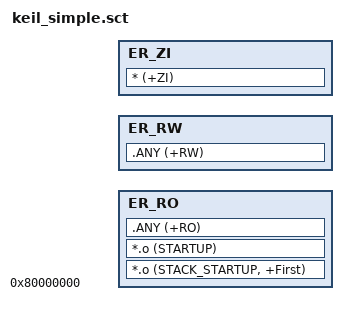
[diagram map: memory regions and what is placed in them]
; *************************************************************
; *** Scatter-Loading Description File generated by uVision ***
; *************************************************************
; Use SDRAM at EMC_DYCS0 (32MByte x 32-bits)

LR_SDRAM 0x80000000 0x02000000  {    ; load region size_region
  ER_RO +0  ; load address = execution address
  {
    *.o (STACK_STARTUP, +First)
    *.o (STARTUP)
    .ANY (+RO)
  }
  
  ER_RW +0
  {
    .ANY (+RW)
  }

  ER_ZI +0        
  {
    * (+ZI)
  }
}
